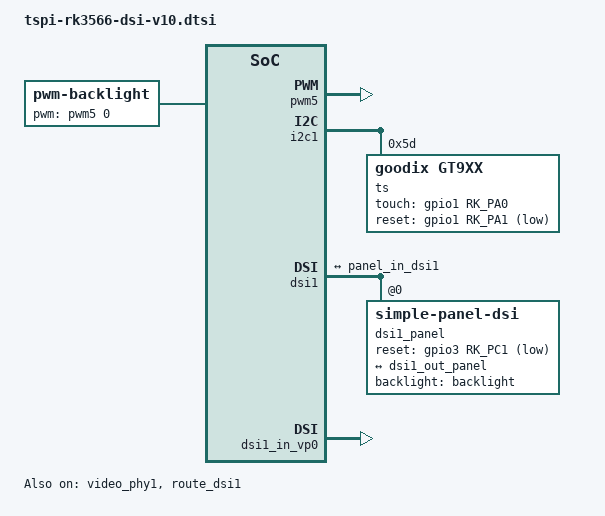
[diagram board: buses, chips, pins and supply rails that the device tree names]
/********************************************************************
 * 共建开源生态是我们的目标。为此我们努力把性价比和颜值做到极致。
 * 同时全面开放SDK、原理图、PCB等所有软硬件资料。
 * 提供交流平台、免费训练营、开发者扶持计划等，让您能够尽情发挥您的才华。
 * 我们坚信自由和定制化是开源生态的核心。
 * 泰山派开发板不仅仅是立创开发板的产品，它更是我们共同努力的成果。
 * 我们只是抛砖引玉，期望能够激发出更多的创意和想法。
 * 我们渴望与志同道合的伙伴们携手合作，共同探索无限可能。
 * 让我们各展所长，共同建设一个强大的开源生态系统。
 * 泰山派开发板等待着您的加入。
 * 让我们一起推动技术的前进，一起创未来！
 *********************************************************************
 * 立创开发板不靠卖板赚钱，以培养中国工程师为己任。  
 * 开发板官网：www.lckfb.com
 * 嘉立创论坛：www.jlc-bbs.com/lckfb 
 * 资料教程：wiki.lckfb.com  
 * 开源项目：https://oshwhub.com/search?wd=%E6%B3%B0%E5%B1%B1%E6%B4%BE   
 * 关注B站：【立创开发板】，掌握我们的最新动态！  
 *********************************************************************/
 
/ {
	backlight: backlight {
		compatible = "pwm-backlight";
		pwms = <&pwm5 0 25000 0>;
		brightness-levels = <
			  0  20  20  21  21  22  22  23
			 23  24  24  25  25  26  26  27
			 27  28  28  29  29  30  30  31
			 31  32  32  33  33  34  34  35
			 35  36  36  37  37  38  38  39
			 40  41  42  43  44  45  46  47
			 48  49  50  51  52  53  54  55
			 56  57  58  59  60  61  62  63
			 64  65  66  67  68  69  70  71
			 72  73  74  75  76  77  78  79
			 80  81  82  83  84  85  86  87
			 88  89  90  91  92  93  94  95
			 96  97  98  99 100 101 102 103
			104 105 106 107 108 109 110 111
			112 113 114 115 116 117 118 119
			120 121 122 123 124 125 126 127
			128 129 130 131 132 133 134 135
			136 137 138 139 140 141 142 143
			144 145 146 147 148 149 150 151
			152 153 154 155 156 157 158 159
			160 161 162 163 164 165 166 167
			168 169 170 171 172 173 174 175
			176 177 178 179 180 181 182 183
			184 185 186 187 188 189 190 191
			192 193 194 195 196 197 198 199
			200 201 202 203 204 205 206 207
			208 209 210 211 212 213 214 215
			216 217 218 219 220 221 222 223
			224 225 226 227 228 229 230 231
			232 233 234 235 236 237 238 239
			240 241 242 243 244 245 246 247
			248 249 250 251 252 253 254 255
		>;
		default-brightness-level = <255>;
	};
};

&pwm5 {
	status = "okay";
};

&i2c1 {
	status = "okay";
	ts@5d {
		compatible = "goodix,gt9xx";
		reg = <0x5d>;
		tp-size = <89>;
		max-x = <1280>;
		max-y = <800>;
		touch-gpio = <&gpio1 RK_PA0 IRQ_TYPE_LEVEL_LOW>;
		reset-gpio = <&gpio1 RK_PA1 GPIO_ACTIVE_LOW>;
	};
};

&pinctrl {
	dsi1 {
		dsi1_rst_gpio: dsi1-rst-gpio {
			rockchip,pins = <3 RK_PC1 RK_FUNC_GPIO &pcfg_pull_none>;
		};
	};
};

/*
 * video_phy1 needs to be enabled
 * when dsi1 is enabled
 */
&dsi1 {
	status = "okay";
};

&dsi1_in_vp0 {
	status = "okay";
};

&dsi1_in_vp1 {
	status = "disabled";
};

&video_phy1 {
	status = "okay";
};

&route_dsi1 {
	status = "okay";
	connect = <&vp0_out_dsi1>;
};

&dsi1 {
	status = "okay";
	rockchip,lane-rate = <500>;
	dsi1_panel: panel@0 {
		status = "okay";
		compatible = "simple-panel-dsi";
		reset-gpios = <&gpio3 RK_PC1 GPIO_ACTIVE_LOW>;
		pinctrl-names = "default";
		pinctrl-0 = <&dsi1_rst_gpio>;
		reg = <0>;
		backlight = <&backlight>;
		reset-delay-ms = <30>;
		enable-delay-ms = <100>;
		prepare-delay-ms = <20>;
		unprepare-delay-ms = <20>;
		disable-delay-ms = <20>;
        width-mm = <68>;
		height-mm = <121>;
		init-delay-ms = <10>;
		dsi,flags = <(MIPI_DSI_MODE_VIDEO | MIPI_DSI_MODE_VIDEO_BURST |
			MIPI_DSI_MODE_LPM | MIPI_DSI_MODE_EOT_PACKET)>;
		dsi,format = <MIPI_DSI_FMT_RGB888>;
		dsi,lanes  = <4>;
		panel-init-sequence = [
			39 00 04 FF 98 81 03
			15 00 02 01 00
			15 00 02 02 00
			15 00 02 03 53    
			15 00 02 04 53    
			15 00 02 05 13
			15 00 02 06 04
			15 00 02 07 02
			15 00 02 08 02
			15 00 02 09 00
			15 00 02 0a 00
			15 00 02 0b 00
			15 00 02 0c 00
			15 00 02 0d 00
			15 00 02 0e 00
			15 00 02 0f 00
			15 00 02 10 00
			15 00 02 11 00
			15 00 02 12 00
			15 00 02 13 00
			15 00 02 14 00
			15 00 02 15 00
			15 00 02 16 00
			15 00 02 17 00
			15 00 02 18 00
			15 00 02 19 00
			15 00 02 1a 00
			15 00 02 1b 00
			15 00 02 1c 00
			15 00 02 1d 00
			15 00 02 1e c0
			15 00 02 1f 00
			15 00 02 20 02
			15 00 02 21 09
			15 00 02 22 00
			15 00 02 23 00
			15 00 02 24 00
			15 00 02 25 00
			15 00 02 26 00
			15 00 02 27 00
			15 00 02 28 55
			15 00 02 29 03
			15 00 02 2a 00
			15 00 02 2b 00
			15 00 02 2c 00
			15 00 02 2d 00
			15 00 02 2e 00
			15 00 02 2f 00
			15 00 02 30 00
			15 00 02 31 00
			15 00 02 32 00
			15 00 02 33 00
			15 00 02 34 00
			15 00 02 35 00
			15 00 02 36 00
			15 00 02 37 00
			15 00 02 38 3C
			15 00 02 39 00
			15 00 02 3a 00
			15 00 02 3b 00
			15 00 02 3c 00
			15 00 02 3d 00
			15 00 02 3e 00
			15 00 02 3f 00
			15 00 02 40 00
			15 00 02 41 00
			15 00 02 42 00
			15 00 02 43 00
			15 00 02 44 00
			
			15 00 02 50 01
			15 00 02 51 23
			15 00 02 52 45
			15 00 02 53 67
			15 00 02 54 89
			15 00 02 55 ab
			15 00 02 56 01
			15 00 02 57 23
			15 00 02 58 45
			15 00 02 59 67
			15 00 02 5a 89
			15 00 02 5b ab
			15 00 02 5c cd
			15 00 02 5d ef

			15 00 02 5e 01
			15 00 02 5f 0A    
			15 00 02 60 02    
			15 00 02 61 02    
			15 00 02 62 08    
			15 00 02 63 15    
			15 00 02 64 14    
			15 00 02 65 02    
			15 00 02 66 11    
			15 00 02 67 10    
			15 00 02 68 02    
			15 00 02 69 0F    
			15 00 02 6a 0E    
			15 00 02 6b 02    
			15 00 02 6c 0D    
			15 00 02 6d 0C    
			15 00 02 6e 06    
			15 00 02 6f 02    
			15 00 02 70 02    
			15 00 02 71 02    
			15 00 02 72 02    
			15 00 02 73 02    
			15 00 02 74 02    
			
			15 00 02 75 0A    
			15 00 02 76 02    
			15 00 02 77 02    
			15 00 02 78 06    
			15 00 02 79 15    
			15 00 02 7a 14    
			15 00 02 7b 02    
			15 00 02 7c 10    
			15 00 02 7d 11    
			15 00 02 7e 02    
			15 00 02 7f 0C    
			15 00 02 80 0D    
			15 00 02 81 02    
			15 00 02 82 0E    
			15 00 02 83 0F    
			15 00 02 84 08    
			15 00 02 85 02    
			15 00 02 86 02    
			15 00 02 87 02    
			15 00 02 88 02    
			15 00 02 89 02    
			15 00 02 8A 02    


			39 00 04 FF 98 81 04
			//15 00 02 00 00  //
			// 15 00 02 2F 01   //bist 用户调试，屏幕会闪演示测试
			15 00 02 3B C0  
			15 00 02 6C 15
			15 00 02 6E 30  
			15 00 02 6F 55  
			15 00 02 3A 24
			15 00 02 8D 1F
			15 00 02 87 BA
			15 00 02 26 76
			15 00 02 B2 D1
			15 00 02 B5 07
			15 00 02 35 1F
			15 00 02 88 0B
			15 00 02 21 09


			39 00 04 FF 98 81 01
			15 00 02 22 0A
			15 00 02 31 09
			15 00 02 40 33
			15 00 02 53 37
			15 00 02 55 38
			15 00 02 50 95
			15 00 02 51 95
			15 00 02 60 30

			15 00 02 A0 0F        
			15 00 02 A1 17        
			15 00 02 A2 22        
			15 00 02 A3 19        
			15 00 02 A4 15        
			15 00 02 A5 28        
			15 00 02 A6 1C        
			15 00 02 A7 1C        
			15 00 02 A8 78        
			15 00 02 A9 1C        
			15 00 02 AA 28        
			15 00 02 AB 69        
			15 00 02 AC 1A        
			15 00 02 AD 19        
			15 00 02 AE 4B        
			15 00 02 AF 22        
			15 00 02 B0 2A        
			15 00 02 B1 4B        
			15 00 02 B2 6B        
			15 00 02 B3 3F        

			15 00 02 C0 01        
			15 00 02 C1 17        
			15 00 02 C2 22        
			15 00 02 C3 19        
			15 00 02 C4 15        
			15 00 02 C5 28        
			15 00 02 C6 1C        
			15 00 02 C7 1D        
			15 00 02 C8 78        
			15 00 02 C9 1C        
			15 00 02 CA 28        
			15 00 02 CB 69        
			15 00 02 CC 1A        
			15 00 02 CD 19        
			15 00 02 CE 4B        
			15 00 02 CF 22        
			15 00 02 D0 2A        
			15 00 02 D1 4B        
			15 00 02 D2 6B        
			15 00 02 D3 3F        
			39 00 04 FF 98 81 00		
			05 78 01 11
			05 14 01 29
		];

		panel-exit-sequence = [
			05 00 01 28
			05 00 01 10
		];

		disp_timings1: display-timings {
			native-mode = <&dsi1_timing0>;
			dsi1_timing0: timing0 {
				clock-frequency = <71000000>;
				hactive = <800>;
				vactive = <1280>;
				hfront-porch = <52>;
				hsync-len = <8>;
				hback-porch = <48>;
				vfront-porch = <15>;
				vsync-len = <6>;
				vback-porch = <16>;
				hsync-active = <0>;
				vsync-active = <0>;
				de-active = <0>;
				pixelclk-active = <0>;
			};
		};

		ports {
			#address-cells = <1>;
			#size-cells = <0>;

			port@0 {
				reg = <0>;
				panel_in_dsi1: endpoint {
					remote-endpoint = <&dsi1_out_panel>;
				};
			};
		};
	};

	ports {
		#address-cells = <1>;
		#size-cells = <0>;

		port@1 {
			reg = <1>;
			dsi1_out_panel: endpoint {
				remote-endpoint = <&panel_in_dsi1>;
			};
		};
	};

};

